# N32F030 register map
File version: 1.0
Registers are 32-bit, read-write, reset 0x0 unless marked. A register's access mark holds for its fields unless they carry their own. Offsets are from the block's base; [hi:lo] are bit positions; {n}, {i} and the like mark numbered series; 'fields as' and 'values as' point back to an identical list.

## ADC — ADC Register Map
Base 0x400E0000
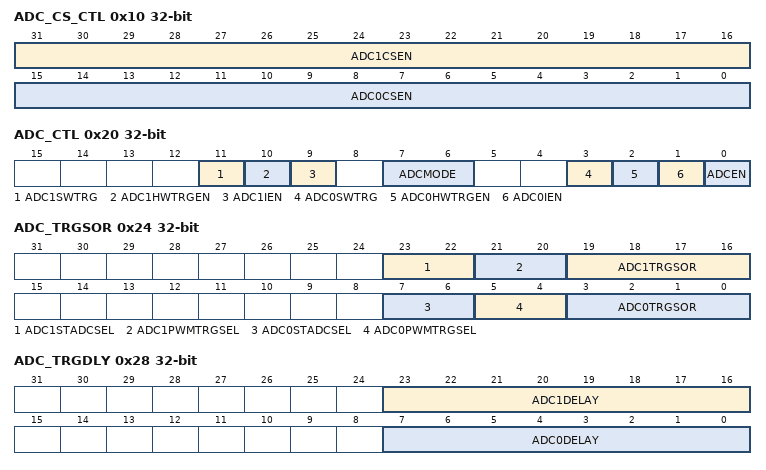
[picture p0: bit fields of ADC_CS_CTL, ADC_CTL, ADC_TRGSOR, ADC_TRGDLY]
0x10 ADC_CS_CTL — ADC Channel Select Control Register
  [31:16] ADC1CSEN — ADC1(SH1) Channel Select Enable
  [15:0] ADC0CSEN — ADC0(SH0) Channel Select Enable
0x20 ADC_CTL — ADC Control Register
  [11] ADC1SWTRG — ADC1 Conversion Start. Note: ADC1SWTRG will be set to '1' when any of ADC1 trigger event happen or user also can write '1' to this bit to demand a software ADC1 trigger, when hardware finish the conversion it will be cleared to '0' automatically.
    0=Conversion stopped and A/D converter entered idle state; 1=Start ADC1 and indicate there has ADC1 conversion request
  [10] ADC1HWTRGEN — Hardware Trigger ADC Conversion Enable Control. Enable or disable triggering of A/D conversion by Hardware (PWM, Timer, ECAP and ADC self)
    0=Disable ADC1 hardware trigger function; 1=Enable ADC1 hardware trigger function
  [9] ADC1IEN — ADC1 Interrupt Enable Control. Note: If ADC1IEN bit is set to 1 the ADC1_INT is requested by the end of ADC conversion.
    0=Disable ADC1 interrupt; 1=Enable ADC1 interrupt
  [7:6] ADCMODE — A/D Conversion Mode
    0=Independent Mode, independent trigger function and independent interrupt; 2=Simultaneous Mode, simultaneously triggered by ADC0, ADC0 and ADC1 convert sequentially then only interrupt ADC0IF is generated; 3=Simultaneous Mode, simultaneously triggered by ADC0, ADC0 and ADC1 convert sequentially then only interrupt ADC0IF is generated
  [3] ADC0SWTRG — ADC0 Conversion Start. Note: ADC0SWTRG will be set to '1' when any of ADC0 trigger event happen or user also can write '1' to this bit to demand a software ADC0 trigger, when hardware finish the conversion it will be cleared to '0' automatically.
    0=Conversion stopped and A/D converter entered idle state; 1=Start ADC0 and indicate there has ADC0 conversion request
  [2] ADC0HWTRGEN — Hardware Trigger ADC Convertion Enable Bit. Enable or disable triggering of A/D conversion by Hardware (PWM, Timer, ECAP and ADC self)
    0=Disable ADC0 hardware trigger function; 1=Enable ADC0 hardware trigger function
  [1] ADC0IEN — ADC0 Interrupt Enable Bit. Note: If ADC0IEN bit is set to 1 the ADC0_INT is requested by the end of ADC conversion.
    0=Disable ADC0 interrupt; 1=Enable ADC0 interrupt
  [0] ADCEN — ADC Converter Enable Bit. Note: Before starting the A/D conversion function, this bit should be set to '1'. Clear it to '0' to disable A/D converter analog circuit power consumption.
    0=Disable ADC Converter; 1=Enable ADC Converter
0x24 ADC_TRGSOR — ADC Hardware Trigger Source Control Register
  [23:22] ADC1STADCSEL — ADC1 External Trigger Pin (STADC) Trigger Selection
    0=Rising; 1=Falling; 2=Rising or Falling
  [21:20] ADC1PWMTRGSEL — PWM Trigger Selection for ADC1
    0=EPWM Signal Falling. (Not available in edge-aligned type); 1=EPWM Counter Central. (Not available in edge-aligned type); 2=EPWM signal Rising; 3=Period
  [19:16] ADC1TRGSOR — ADC1 Trigger Source
    0=STADC; {v}=PWM{v-1} (v=1..6); 7=TMR0_MATCH. (refer to Figure 6.61 Timer Controller Block Diagram); 8=TMR1_MATCH. (refer to Figure 6.61 Timer Controller Block Diagram); 9=ECAPPHG_TRG. (From ECAP, CPAEN (CAPTF0| CAPTF1| CAPTF2); 10=ADC0IF; 11=ADC1IF
  [7:6] ADC0STADCSEL — ADC0 External Trigger Pin (STADC) Trigger Selection
    0=Rising; 1=Falling; 2=Rising or Falling
  [5:4] ADC0PWMTRGSEL — PWM Trigger Selection for ADC0
    values as ADC1PWMTRGSEL
  [3:0] ADC0TRGSOR — ADC0 Trigger Source
    values as ADC1TRGSOR
0x28 ADC_TRGDLY — ADC Trigger Delay Control Register
  [23:16] ADC1DELAY — ADC1 Trigger Delay Timer. Setting this field will insert a delay time from H/W tirgger condition happens to conversion starts. Delay time is (4 * ADC1DELAY) * system clock. Note: Software trigger does not support delay-time insertion.
  [7:0] ADC0DELAY — ADC0 Trigger Delay Timer. Setting this field will insert a delay time from H/W tirgger condition happens to conversion starts. Delay time is (4 * ADC0DELAY) * system clock. Note: Software trigger does not support delay-time insertion.
0x2C ADC_SMPCNT reset 0x5 — ADC Sampling Time Counter Register
  [3:0] ADCSMPCNT — ADC Sampling Counter. For normal channel:
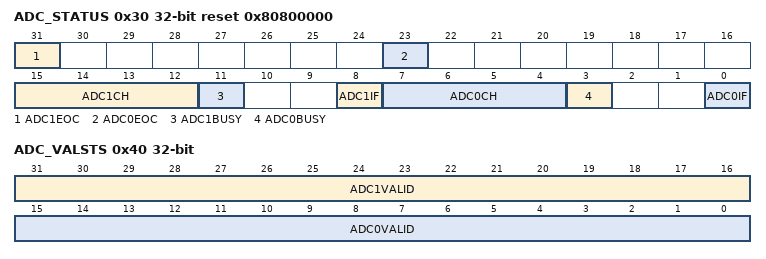
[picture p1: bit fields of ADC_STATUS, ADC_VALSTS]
0x30 ADC_STATUS reset 0x80800000
  [31] ADC1EOC — ADC1 end of convert.
  [23] ADC0EOC — ADC0 end of convert.
  [15:12] ADC1CH — Current Conversion Channel. It is read only.
  [11] ADC1BUSY — BUSY/IDLE
    0=A/D converter is in idle state; 1=A/D converter is busy at conversion
  [8] ADC1IF — ADC1 Conversion End Flag. A status flag that indicates the end of A/D conversion. ADF is set to '1' When A/D conversion ends. This flag can be cleared by writing '1' to itself.
  [7:4] ADC0CH — Current Conversion Channel. It is read only.
  [3] ADC0BUSY — BUSY/IDLE
    values as ADC1BUSY
  [0] ADC0IF — A/D Conversion End Flag. A status flag that indicates the end of A/D conversion. ADF is set to '1' When A/D conversion ends. This flag can be cleared by writing '1' to itself.
0x40 ADC_VALSTS — ADC Valid Status Register
  [31:16] ADC1VALID — Bits set 1 when ADC1 CHn convertion is finished, and it is automatically cleared when ADC1_DATn is read.
  [15:0] ADC0VALID — Bits set 1 when ADC0 CHn convertion is finished, and it is automatically cleared when ADC0_DATn is read.
{0x80+4i} ADC0_DAT{i} ro (i=0..15) — ADC0 Data Register n
  [11:0] ADC0DAT — ADC0 Conversion Result. This field contains conversion result of ADC0_CHn.
{0xC0+4i} ADC1_DAT{i} ro (i=0..15) — ADC1 Data Register n
  [11:0] ADC1DAT — ADC1 Conversion Result. This field contains conversion result of ADC1_CHn.
